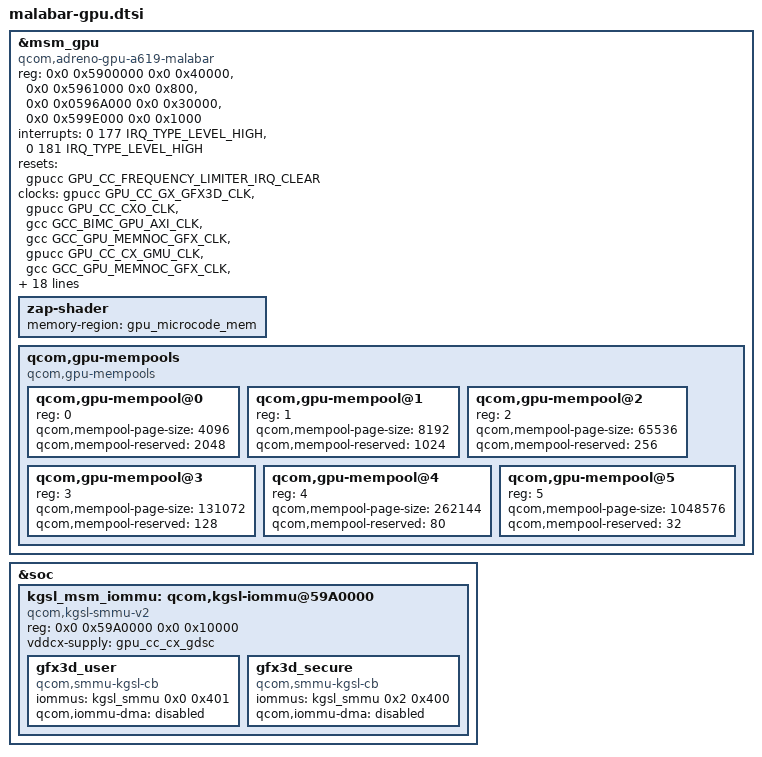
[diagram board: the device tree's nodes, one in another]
// SPDX-License-Identifier: BSD-3-Clause
/*
 * Copyright (c) Qualcomm Technologies, Inc. and/or its subsidiaries.
 */

#include <dt-bindings/regulator/qcom,rpm-smd-regulator.h>
#define MHZ_TO_KBPS(mhz, w) ((mhz * 1000000 * w) / (1024))

/* External feature codes */
#define FC_UNKNOWN 0x0
#define FC_AB 0x2

/* SubPart feature code */
#define FC_W0 0x00d1
#define FC_W1 0x00d2

/* Internal feature codes */
#define FC_Y0 0x00f1
#define FC_Y1 0x00f2

/* Pcodes */
#define PCODE_UNKNOWN 0
#define PCODE_0 1
#define PCODE_1 2
#define PCODE_2 3

#define SKU_CODE(pcode, featurecode) ((pcode << 16) + featurecode)

&msm_gpu {
	compatible = "qcom,adreno-gpu-a619-malabar", "qcom,kgsl-3d0";
	status = "ok";
	reg = <0x0 0x5900000 0x0 0x40000>, <0x0 0x5961000 0x0 0x800>,
		<0x0 0x0596A000 0x0 0x30000>, <0x0 0x599E000 0x0 0x1000>;
	reg-names = "kgsl_3d0_reg_memory", "cx_dbgc", "gmu_wrapper",
		"cx_misc";

	interrupts = <0 177 IRQ_TYPE_LEVEL_HIGH>, <0 181 IRQ_TYPE_LEVEL_HIGH>;
	interrupt-names = "kgsl_3d0_irq", "freq_limiter_irq";

	resets = <&gpucc GPU_CC_FREQUENCY_LIMITER_IRQ_CLEAR>;
	reset-names = "freq_limiter_irq_clear";

	clocks = <&gpucc GPU_CC_GX_GFX3D_CLK>,
		<&gpucc GPU_CC_CXO_CLK>,
		<&gcc GCC_BIMC_GPU_AXI_CLK>,
		<&gcc GCC_GPU_MEMNOC_GFX_CLK>,
		<&gpucc GPU_CC_CX_GMU_CLK>,
		<&gcc GCC_GPU_MEMNOC_GFX_CLK>,
		<&gpucc GPU_CC_AHB_CLK>,
		<&gpucc GPU_CC_HLOS1_VOTE_GPU_SMMU_CLK>;

	clock-names = "core_clk",
		"rbbmtimer_clk",
		"iface_clk",
		"mem_clk",
		"gmu_clk",
		"gcc_gpu_memnoc_gfx",
		"gpu_cc_ahb",
		"gpu_cc_hlos1_vote_gpu_smmu";

	qcom,min-access-length = <32>;

	qcom,ubwc-mode = <2>;

	interconnects = <&bimc MASTER_GRAPHICS_3D &bimc SLAVE_EBI_CH0>;
	interconnect-names = "gpu_icc_path";

	qcom,bus-table-cnoc =
		<0>,   /* Off */
		<100>; /* On */

	qcom,bus-table-ddr =
			<MHZ_TO_KBPS(0, 4)>,    /* index=0  */
			<MHZ_TO_KBPS(200, 4)>,  /* index=1 (LOW SVS) */
			<MHZ_TO_KBPS(547, 4)>,  /* index=2 (LOW SVS) */
			<MHZ_TO_KBPS(768, 4)>,  /* index=3 (SVS) */
			<MHZ_TO_KBPS(1017, 4)>, /* index=4 (SVS) */
			<MHZ_TO_KBPS(1353, 4)>, /* index=5 (NOM) */
			<MHZ_TO_KBPS(1555, 4)>, /* index=6 (NOM) */
			<MHZ_TO_KBPS(1804, 4)>, /* index=7 (TURBO) */
			<MHZ_TO_KBPS(2092, 4)>; /* index=8 (TURBO_L1) */

	/* GDSC regulator names */
	regulator-names = "vddcx", "vdd";

	/* GDSC oxili regulators */
	vddcx-supply = <&gpu_cc_cx_gdsc>;
	vdd-supply = <&gpu_cc_gx_gdsc>;
	vdd-parent-supply = <&VDD_GFX_LEVEL>;
	vdd-parent-min-corner = <RPM_SMD_REGULATOR_LEVEL_RETENTION>;

	zap-shader {
		memory-region = <&gpu_microcode_mem>;
	};

	qcom,gpu-mempools {
		#address-cells = <1>;
		#size-cells = <0>;
		compatible = "qcom,gpu-mempools";

		/* 4K Page Pool configuration */
		qcom,gpu-mempool@0 {
			reg = <0>;
			qcom,mempool-page-size = <4096>;
			qcom,mempool-reserved = <2048>;
		};
		/* 8K Page Pool configuration */
		qcom,gpu-mempool@1 {
			reg = <1>;
			qcom,mempool-page-size = <8192>;
			qcom,mempool-reserved = <1024>;
		};
		/* 64K Page Pool configuration */
		qcom,gpu-mempool@2 {
			reg = <2>;
			qcom,mempool-page-size = <65536>;
			qcom,mempool-reserved = <256>;
		};
		/* 128K Page Pool configuration */
		qcom,gpu-mempool@3 {
			reg = <3>;
			qcom,mempool-page-size = <131072>;
			qcom,mempool-reserved = <128>;
		};
		/* 256K Page Pool configuration */
		qcom,gpu-mempool@4 {
			reg = <4>;
			qcom,mempool-page-size = <262144>;
			qcom,mempool-reserved = <80>;
		};
		/* 1M Page Pool configuration */
		qcom,gpu-mempool@5 {
			reg = <5>;
			qcom,mempool-page-size = <1048576>;
			qcom,mempool-reserved = <32>;
		};
	};
};

&soc {
	kgsl_msm_iommu: qcom,kgsl-iommu@59A0000 {
		compatible = "qcom,kgsl-smmu-v2";
		reg = <0x0 0x59A0000 0x0 0x10000>;

		vddcx-supply = <&gpu_cc_cx_gdsc>;

		gfx3d_user: gfx3d_user {
			compatible = "qcom,smmu-kgsl-cb";
			iommus = <&kgsl_smmu 0x0 0x401>;
			qcom,iommu-dma = "disabled";
		};

		gfx3d_secure: gfx3d_secure {
			compatible = "qcom,smmu-kgsl-cb";
			iommus = <&kgsl_smmu 0x2 0x400>;
			qcom,iommu-dma = "disabled";
		};
	};
};
